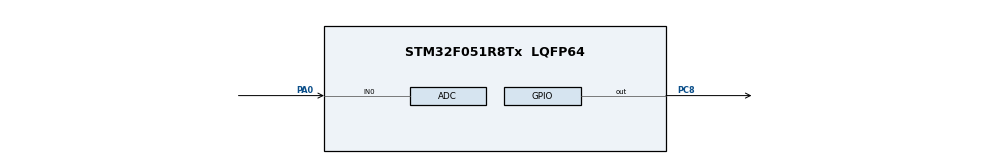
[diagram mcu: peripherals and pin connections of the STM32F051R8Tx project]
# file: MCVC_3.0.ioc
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ADC.ContinuousConvMode=ENABLE
ADC.ExternalTrigConv=ADC_EXTERNALTRIGCONV_T15_TRGO
ADC.ScanConvMode=ADC_SCAN_DIRECTION_BACKWARD
FREERTOS.BinarySemaphores01=SemaphoreLed,Dynamic,NULL
FREERTOS.Tasks01=defaultTask,0,128,StartDefaultTask,Default,NULL,Dynamic,NULL,NULL;TaskLed,0,128,StartTaskLed,Default,NULL,Dynamic,NULL,NULL
Mcu.Family=STM32F0
Mcu.Name=STM32F051R8Tx
Mcu.Package=LQFP64
NVIC.TIM15_IRQn=true\:3\:0\:false\:false\:true\:true\:true\:true\:true
NVIC.TIM6_DAC_IRQn=true\:3\:0\:false\:false\:true\:false\:false\:true\:true
NVIC.TimeBase=TIM6_DAC_IRQn
NVIC.TimeBaseIP=TIM6
PA0.Mode=IN0
PA0.Signal=ADC_IN0
PA13.Mode=Serial_Wire
PA13.Signal=SYS_SWDIO
PA14.Mode=Serial_Wire
PA14.Signal=SYS_SWCLK
PC8.Signal=GPIO_Output
ProjectManager.HeapSize=0x200
ProjectManager.StackSize=0x400
ProjectManager.TargetToolchain=MDK-ARM V5.32
TIM15.Prescaler=0
TIM15.TIM_MasterOutputTrigger=TIM_TRGO_UPDATE
VP_FREERTOS_VS_CMSIS_V1.Mode=CMSIS_V1
VP_SYS_VS_tim6.Mode=TIM6
VP_TIM15_VS_ClockSourceINT.Mode=Internal
board=custom

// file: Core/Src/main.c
/* USER CODE BEGIN Header */
/**
  ******************************************************************************
  * @file           : main.c
  * @brief          : Main program body
  ******************************************************************************
  * @attention
  *
  * Copyright (c) 2023 STMicroelectronics.
  * All rights reserved.
  *
  * This software is licensed under terms that can be found in the LICENSE file
  * in the root directory of this software component.
  * If no LICENSE file comes with this software, it is provided AS-IS.
  *
  ******************************************************************************
  */
/* USER CODE END Header */
#include "main.h"
#include "cmsis_os.h"
#include "adc.h"
#include "tim.h"
#include "gpio.h"

/* USER CODE BEGIN PV */
extern osSemaphoreId SemaphoreLedHandle;
/* USER CODE END PV */

void SystemClock_Config(void);
void MX_FREERTOS_Init(void);

int main(void)
{

  /* MCU Configuration--------------------------------------------------------*/

  /* Reset of all peripherals, Initializes the Flash interface and the Systick. */
  HAL_Init();

  /* Configure the system clock */
  SystemClock_Config();

  /* Initialize all configured peripherals */
  MX_GPIO_Init();
  MX_ADC_Init();
  MX_TIM15_Init();
  /* USER CODE BEGIN 2 */
	HAL_TIM_Base_Start(&htim15);
  /* USER CODE END 2 */

  /* Call init function for freertos objects (in freertos.c) */
  MX_FREERTOS_Init();

  /* Start scheduler */
  osKernelStart();

  /* We should never get here as control is now taken by the scheduler */
  /* Infinite loop */
  while (1)
  {

  }
}

void SystemClock_Config(void)
{
  RCC_OscInitTypeDef RCC_OscInitStruct = {0};
  RCC_ClkInitTypeDef RCC_ClkInitStruct = {0};

  /** Initializes the RCC Oscillators according to the specified parameters
  * in the RCC_OscInitTypeDef structure.
  */
  RCC_OscInitStruct.OscillatorType = RCC_OSCILLATORTYPE_HSI|RCC_OSCILLATORTYPE_HSI14;
  RCC_OscInitStruct.HSIState = RCC_HSI_ON;
  RCC_OscInitStruct.HSI14State = RCC_HSI14_ON;
  RCC_OscInitStruct.HSICalibrationValue = RCC_HSICALIBRATION_DEFAULT;
  RCC_OscInitStruct.HSI14CalibrationValue = 16;
  RCC_OscInitStruct.PLL.PLLState = RCC_PLL_NONE;
  if (HAL_RCC_OscConfig(&RCC_OscInitStruct) != HAL_OK)
  {
    Error_Handler();
  }

  /** Initializes the CPU, AHB and APB buses clocks
  */
  RCC_ClkInitStruct.ClockType = RCC_CLOCKTYPE_HCLK|RCC_CLOCKTYPE_SYSCLK
                              |RCC_CLOCKTYPE_PCLK1;
  RCC_ClkInitStruct.SYSCLKSource = RCC_SYSCLKSOURCE_HSI;
  RCC_ClkInitStruct.AHBCLKDivider = RCC_SYSCLK_DIV1;
  RCC_ClkInitStruct.APB1CLKDivider = RCC_HCLK_DIV1;

  if (HAL_RCC_ClockConfig(&RCC_ClkInitStruct, FLASH_LATENCY_0) != HAL_OK)
  {
    Error_Handler();
  }
}

void HAL_TIM_PeriodElapsedCallback(TIM_HandleTypeDef *htim)
{
  if (htim->Instance == TIM6) {
    HAL_IncTick();
  }
}

void Error_Handler(void)
{
  __disable_irq();
  while (1)
  {
  }
}

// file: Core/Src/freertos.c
/* USER CODE BEGIN Header */
/**
  ******************************************************************************
  * File Name          : freertos.c
  * Description        : Code for freertos applications
  ******************************************************************************
  * @attention
  *
  * Copyright (c) 2023 STMicroelectronics.
  * All rights reserved.
  *
  * This software is licensed under terms that can be found in the LICENSE file
  * in the root directory of this software component.
  * If no LICENSE file comes with this software, it is provided AS-IS.
  *
  ******************************************************************************
  */
/* USER CODE END Header */

#include "FreeRTOS.h"
#include "task.h"
#include "main.h"
#include "cmsis_os.h"

/* USER CODE BEGIN Variables */
extern ADC_HandleTypeDef hadc;
uint32_t ulADC_Value;
int32_t slSemCond;
BaseType_t SemVal;
/* USER CODE END Variables */
osThreadId defaultTaskHandle;
osThreadId TaskLedHandle;
osSemaphoreId SemaphoreLedHandle;

void StartDefaultTask(void const * argument);
void StartTaskLed(void const * argument);

void MX_FREERTOS_Init(void); /* (MISRA C 2004 rule 8.1) */

/* GetIdleTaskMemory prototype (linked to static allocation support) */
void vApplicationGetIdleTaskMemory( StaticTask_t **ppxIdleTaskTCBBuffer, StackType_t **ppxIdleTaskStackBuffer, uint32_t *pulIdleTaskStackSize );

/* USER CODE BEGIN GET_IDLE_TASK_MEMORY */
static StaticTask_t xIdleTaskTCBBuffer;
static StackType_t xIdleStack[configMINIMAL_STACK_SIZE];

void vApplicationGetIdleTaskMemory( StaticTask_t **ppxIdleTaskTCBBuffer, StackType_t **ppxIdleTaskStackBuffer, uint32_t *pulIdleTaskStackSize )
{
  *ppxIdleTaskTCBBuffer = &xIdleTaskTCBBuffer;
  *ppxIdleTaskStackBuffer = &xIdleStack[0];
  *pulIdleTaskStackSize = configMINIMAL_STACK_SIZE;
  /* place for user code */
}
/* USER CODE END GET_IDLE_TASK_MEMORY */

void MX_FREERTOS_Init(void) {

  /* Create the semaphores(s) */
  /* definition and creation of SemaphoreLed */
  osSemaphoreDef(SemaphoreLed);
  SemaphoreLedHandle = osSemaphoreCreate(osSemaphore(SemaphoreLed), 1);

  /* Create the thread(s) */
  /* definition and creation of defaultTask */
  osThreadDef(defaultTask, StartDefaultTask, osPriorityNormal, 0, 128);
  defaultTaskHandle = osThreadCreate(osThread(defaultTask), NULL);

  /* definition and creation of TaskLed */
  osThreadDef(TaskLed, StartTaskLed, osPriorityNormal, 0, 128);
  TaskLedHandle = osThreadCreate(osThread(TaskLed), NULL);

}

void StartDefaultTask(void const * argument)
{
  for(;;)
  {
    osDelay(1);
  }
}

void StartTaskLed(void const * argument)
{
  /* USER CODE BEGIN StartTaskLed */
	HAL_ADC_Start(&hadc);
	HAL_ADCEx_Calibration_Start(&hadc);
  /* Infinite loop */
  for(;;)
  {
		if (HAL_ADC_GetValue(&hadc) > 3000)
			HAL_GPIO_WritePin(GPIOC, GPIO_PIN_8, GPIO_PIN_SET);
		else
			HAL_GPIO_WritePin(GPIOC, GPIO_PIN_8, GPIO_PIN_RESET);
  }
  /* USER CODE END StartTaskLed */
}
